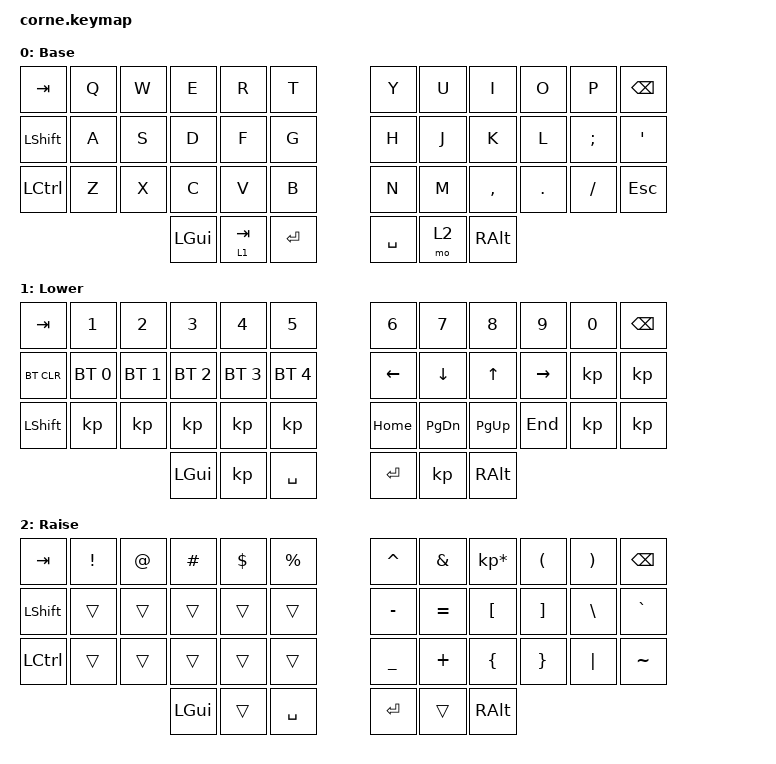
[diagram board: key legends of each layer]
/*
 * Copyright (c) 2020 The ZMK Contributors
 *
 * SPDX-License-Identifier: MIT
 */

#include <behaviors.dtsi>
#include <dt-bindings/zmk/bt.h>
#include <dt-bindings/zmk/keys.h>

/ {
    combos {
        compatible = "zmk,combos";

        Esc {
            bindings = <&kp ESC>;
            key-positions = <0 1>;
            layers = <0>;
        };

        Delete {
            bindings = <&kp DELETE>;
            key-positions = <10 11>;
        };

        Enter {
            bindings = <&kp ENTER>;
            key-positions = <22 23>;
        };

        Grave {
            bindings = <&kp GRAVE>;
            key-positions = <12 13>;
        };

        Tilde {
            bindings = <&kp TILDE>;
            key-positions = <24 25>;
        };
    };

    keymap {
        compatible = "zmk,keymap";

        default_layer {
            // -----------------------------------------------------------------------------------------
            // |  TAB |  Q  |  W  |  E  |  R  |  T  |   |  Y  |  U   |  I  |  O  |  P  | BKSP |
            // | CTRL |  A  |  S  |  D  |  F  |  G  |   |  H  |  J   |  K  |  L  |  ;  |  '   |
            // | SHFT |  Z  |  X  |  C  |  V  |  B  |   |  N  |  M   |  ,  |  .  |  /  | ESC  |
            //                    | GUI | LWR | SPC |   | ENT | RSE  | ALT |

            display-name = "Base";
            bindings = <
&kp TAB    &kp Q  &kp W  &kp E     &kp R      &kp T        &kp Y      &kp U  &kp I      &kp O    &kp P     &kp BSPC
&kp LSHFT  &kp A  &kp S  &kp D     &kp F      &kp G        &kp H      &kp J  &kp K      &kp L    &kp SEMI  &kp SQT
&kp LCTRL  &kp Z  &kp X  &kp C     &kp V      &kp B        &kp N      &kp M  &kp COMMA  &kp DOT  &kp FSLH  &kp ESC
                         &kp LGUI  &lt 1 TAB  &kp ENTER    &kp SPACE  &mo 2  &kp RALT
            >;
        };

        lower_layer {
            // -----------------------------------------------------------------------------------------
            // |  TAB |  1  |  2  |  3  |  4  |  5  |   |  6  |  7  |  8  |  9  |  0  | BKSP |
            // | BTCLR| BT1 | BT2 | BT3 | BT4 | BT5 |   | LFT | DWN |  UP | RGT |     |      |
            // | SHFT |     |     |     |     |     |   |     |     |     |     |     |      |
            //                    | GUI |     | SPC |   | ENT |     | ALT |

            display-name = "Lower";
            bindings = <
&kp TAB     &kp N1        &kp N2        &kp N3        &kp NUMBER_4  &kp NUMBER_5    &kp N6    &kp N7         &kp N8       &kp N9     &kp N0  &kp BSPC
&bt BT_CLR  &bt BT_SEL 0  &bt BT_SEL 1  &bt BT_SEL 2  &bt BT_SEL 3  &bt BT_SEL 4    &kp LEFT  &kp DOWN       &kp UP       &kp RIGHT  &kp     &kp
&kp LSHFT   &kp           &kp           &kp           &kp           &kp             &kp HOME  &kp PAGE_DOWN  &kp PAGE_UP  &kp END    &kp     &kp
                                        &kp LGUI      &kp           &kp SPACE       &kp RET   &kp            &kp RALT
            >;
        };

        raise_layer {
            // -----------------------------------------------------------------------------------------
            // |  TAB |  !  |  @  |  #  |  $  |  %  |   |  ^  |  &  |  *  |  (  |  )  | BKSP |
            // | CTRL |     |     |     |     |     |   |  -  |  =  |  [  |  ]  |  \  |  `   |
            // | SHFT |     |     |     |     |     |   |  _  |  +  |  {  |  }  | "|" |  ~   |
            //                    | GUI |     | SPC |   | ENT |     | ALT |

            display-name = "Raise";
            bindings = <
&kp TAB    &kp EXCL  &kp AT  &kp HASH  &kp DLLR  &kp PRCNT    &kp CARET  &kp AMPS   &kp KP_MULTIPLY  &kp LPAR  &kp RPAR  &kp BSPC
&kp LSHFT  &trans    &trans  &trans    &trans    &trans       &kp MINUS  &kp EQUAL  &kp LBKT         &kp RBKT  &kp BSLH  &kp GRAVE
&kp LCTRL  &trans    &trans  &trans    &trans    &trans       &kp UNDER  &kp PLUS   &kp LBRC         &kp RBRC  &kp PIPE  &kp TILDE
                             &kp LGUI  &trans    &kp SPACE    &kp RET    &trans     &kp RALT
            >;
        };
    };
};
